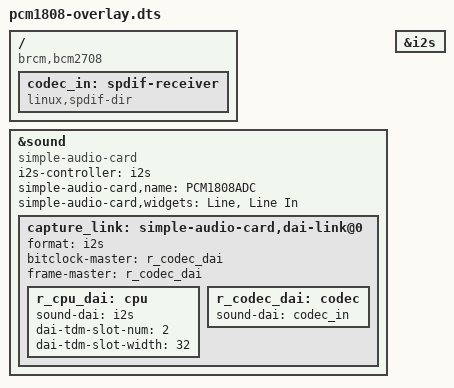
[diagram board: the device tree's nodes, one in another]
//Device tree overlay for PCM1808 using the simple-audio-card in slave mode
//See superaudioboard-overlay.dts for another example
/dts-v1/;
/plugin/;

/ {
    compatible = "brcm,bcm2708";

    fragment@0 {
        target = <&sound>;
        __overlay__ {
            compatible = "simple-audio-card";
	    i2s-controller = <&i2s>; //from SuperAudioBoard
            simple-audio-card,name = "PCM1808ADC";
            status="okay";

	    simple-audio-card,widgets =
		"Line", "Line In";



            capture_link: simple-audio-card,dai-link@0 {
                format = "i2s";

                // Set RasPi to I2S slave
                bitclock-master = <&r_codec_dai>;
                frame-master = <&r_codec_dai>;

                r_cpu_dai: cpu {
                    sound-dai = <&i2s>;

                // TDM slot configuration for stereo
                    dai-tdm-slot-num = <2>;
                    dai-tdm-slot-width = <32>;
                };

                r_codec_dai: codec {
                    sound-dai = <&codec_in>;
                };
            };

            
        };
    };

    fragment@1 {
        target-path = "/";
        __overlay__ {
            
            codec_in: spdif-receiver {
                #address-cells = <0>;
                #size-cells = <0>;
                #sound-dai-cells = <0>;
                /* 
                    "linux,spdif-dir" is used in generic I2S(receiver) driver.                     
                    You can see details "linux,spdif-dir" by bellow command
                    modinfo snd_soc_spdif_rx
                */
                compatible = "linux,spdif-dir";
                status = "okay";
            };
        };
    };

    fragment@2 {
        target = <&i2s>;
        __overlay__ {
            #sound-dai-cells = <0>;
            status = "okay";
        };
    };
};

/* 
Compile with:
   dtc -@ -H epapr -O dtb -o pcm1808-overlay.dtbo -Wno-unit_address_vs_reg pcm1808-overlay.dts
Copy pcm1808-overlay.dtbo to /boot/overlays 
    sudo cp pcm1808-overlay.dtbo /boot/overlays
Edit /boot/config.txt
    sudo nano /boot/config.txt
Edit and add to this line
    # Uncomment some or all of these to enable the optional hardware interface
    #dtparam=i2c_arm=on
    #dtparam=i2s=on
    #dtparam=spi=on

    to

    # Uncomment some or all of these to enable the optional hardware interface
    #dtparam=i2c_arm=on
    dtparam=i2s=on
    #dtparam=spi=on
    dtoverlay=pcm1808-overlay

If you don't need HDMI audio output and RasPi's headphone output, comment out "dtparam=audio=on" by hash.
like this.
    dtparam=audio=on
    to
    #dtparam=audio=on
*/
